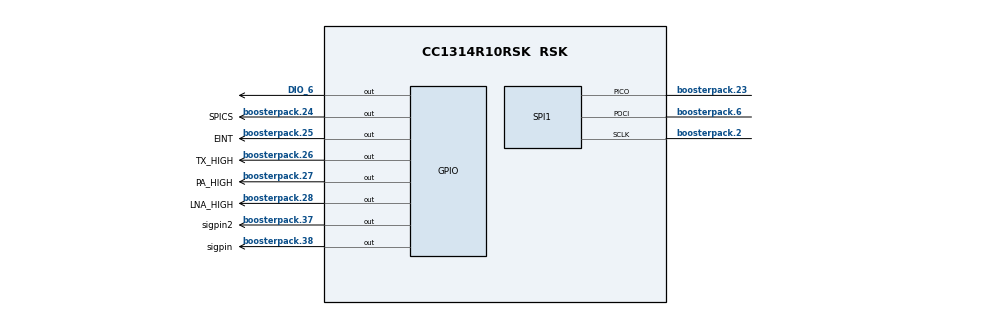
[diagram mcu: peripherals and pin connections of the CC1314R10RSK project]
/**
 * @cliArgs --board "/ti/boards/LP_EM_CC1314R10" --device "CC1314R10RSK" --part "Default" --package "RSK" --rtos "freertos" --product "simplelink_cc13xx_cc26xx_sdk@8.30.01.01"
 * @versions {"tool":"1.21.1+3772"}
 */

/**
 * Import the modules used in this configuration.
 */
const FreeRTOS = scripting.addModule("/freertos/FreeRTOS");
const CCFG     = scripting.addModule("/ti/devices/CCFG");
const custom   = scripting.addModule("/ti/devices/radioconfig/custom");
const rfdesign = scripting.addModule("/ti/devices/radioconfig/rfdesign");
const GPIO     = scripting.addModule("/ti/drivers/GPIO");
const GPIO1    = GPIO.addInstance();
const GPIO2    = GPIO.addInstance();
const GPIO3    = GPIO.addInstance();
const GPIO4    = GPIO.addInstance();
const GPIO5    = GPIO.addInstance();
const GPIO6    = GPIO.addInstance();
const GPIO7    = GPIO.addInstance();
const GPIO8    = GPIO.addInstance();
const GPIO9    = GPIO.addInstance();
const NVS      = scripting.addModule("/ti/drivers/NVS", {}, false);
const NVS1     = NVS.addInstance();
const RF       = scripting.addModule("/ti/drivers/RF");
const SPI      = scripting.addModule("/ti/drivers/SPI", {}, false);
const SPI1     = SPI.addInstance();
const Timer    = scripting.addModule("/ti/drivers/Timer", {}, false);
const Timer1   = Timer.addInstance();
const UART2    = scripting.addModule("/ti/drivers/UART2");
const UART21   = UART2.addInstance();
const UART22   = UART2.addInstance();
const Settings = scripting.addModule("/ti/posix/freertos/Settings");

/**
 * Write custom configuration values to the imported modules.
 */
FreeRTOS.rovQueueEnabled = true;

CCFG.xoscCapArray            = true;
CCFG.xoscCapArrayDelta       = 0xD5;
CCFG.enableBootloader        = true;
CCFG.dioBootloaderBackdoor   = 15;
CCFG.levelBootloaderBackdoor = "Active low";
CCFG.ccfgTemplate.$name      = "ti_devices_CCFG_CCFGCC26XXTemplate0";

custom.prop8                                              = ["custom868"];
custom.radioConfigcustom868.phyType868                    = "2gfsk50kbps";
custom.radioConfigcustom868.carrierFrequency              = 868.0000;
custom.radioConfigcustom868.$name                         = "RF_Custom_Setting";
custom.radioConfigcustom868.whitening                     = "PN9 Whitening";
custom.radioConfigcustom868.symbolRate                    = 1000.000;
custom.radioConfigcustom868.deviation                     = 350.0;
custom.radioConfigcustom868.rxFilterBw                    = "2185.1";
custom.radioConfigcustom868.txPower                       = "12";
custom.radioConfigcustom868.codeExportConfig.$name        = "ti_devices_radioconfig_code_export_param0";
custom.radioConfigcustom868.codeExportConfig.useMulti     = true;
custom.radioConfigcustom868.codeExportConfig.symGenMethod = "Legacy";

rfdesign.rfDesign = "LP_EM_CC1314R10";

GPIO1.$name           = "LNA_HIGH";
GPIO1.mode            = "Output";
GPIO1.gpioPin.$assign = "boosterpack.28";

GPIO2.$hardware = system.deviceData.board.components.LED_GREEN;
GPIO2.$name     = "CONFIG_GPIO_GLED";

GPIO3.$name           = "sigpin2";
GPIO3.mode            = "Output";
GPIO3.gpioPin.$assign = "boosterpack.37";

GPIO4.$name           = "PA_HIGH";
GPIO4.mode            = "Output";
GPIO4.gpioPin.$assign = "boosterpack.27";

GPIO5.$name           = "TX_HIGH";
GPIO5.mode            = "Output";
GPIO5.gpioPin.$assign = "boosterpack.26";

GPIO6.$name           = "CONFIG_GPIO_RLED";
GPIO6.mode            = "Output";
GPIO6.gpioPin.$assign = "DIO_6";
scripting.suppress("Connected to hardware,@@@.+?@@@ is connected to LaunchPad LED Red on the CC1314R10 LaunchPad\\. Consider selecting it in \'use hardware\' above\\. @@@.+?@@@", GPIO6, "gpioPin");

GPIO7.mode               = "Output";
GPIO7.$name              = "SPICS";
GPIO7.initialOutputState = "High";
GPIO7.gpioPin.$assign    = "boosterpack.24";

GPIO8.$name           = "sigpin";
GPIO8.mode            = "Output";
GPIO8.gpioPin.$assign = "boosterpack.38";

GPIO9.$name            = "EINT";
GPIO9.pull             = "Pull Up";
GPIO9.interruptTrigger = "Falling Edge";
GPIO9.gpioPin.$assign  = "boosterpack.25";

NVS1.$name               = "CONFIG_INTERNAL";
NVS1.internalFlash.$name = "ti_drivers_nvs_NVSCC26XX0";

SPI1.$name               = "CONFIG_SPI_0";
SPI1.spi.sclkPin.$assign = "boosterpack.2";
SPI1.spi.pociPin.$assign = "boosterpack.6";
SPI1.spi.picoPin.$assign = "boosterpack.23";

Timer1.$name               = "CONFIG_TIMER_0";
Timer1.timerType           = "32 Bits";
Timer1.timerInstance.$name = "CONFIG_GPTIMER_0";

UART21.$name               = "CONFIG_UART2_0";
UART21.$hardware           = system.deviceData.board.components.XDS110UART;
UART21.txPinInstance.$name = "CONFIG_PIN_UART_TX";
UART21.rxPinInstance.$name = "CONFIG_PIN_UART_RX";

UART22.$name = "CONFIG_UART2_1";

/**
 * Pinmux solution for unlocked pins/peripherals. This ensures that minor changes to the automatic solver in a future
 * version of the tool will not impact the pinmux you originally saw.  These lines can be completely deleted in order to
 * re-solve from scratch.
 */
GPIO2.gpioPin.$suggestSolution              = "DIO_7";
SPI1.spi.$suggestSolution                   = "SPI0";
SPI1.spi.dmaRxChannel.$suggestSolution      = "DMA_CH3";
SPI1.spi.dmaTxChannel.$suggestSolution      = "DMA_CH4";
Timer1.timerInstance.timer.$suggestSolution = "GPTM0";
UART21.uart.$suggestSolution                = "UART1";
UART21.uart.txPin.$suggestSolution          = "boosterpack.4";
UART21.uart.rxPin.$suggestSolution          = "boosterpack.3";
UART22.uart.$suggestSolution                = "UART0";
UART22.uart.txPin.$suggestSolution          = "boosterpack.19";
UART22.uart.rxPin.$suggestSolution          = "boosterpack.39";
